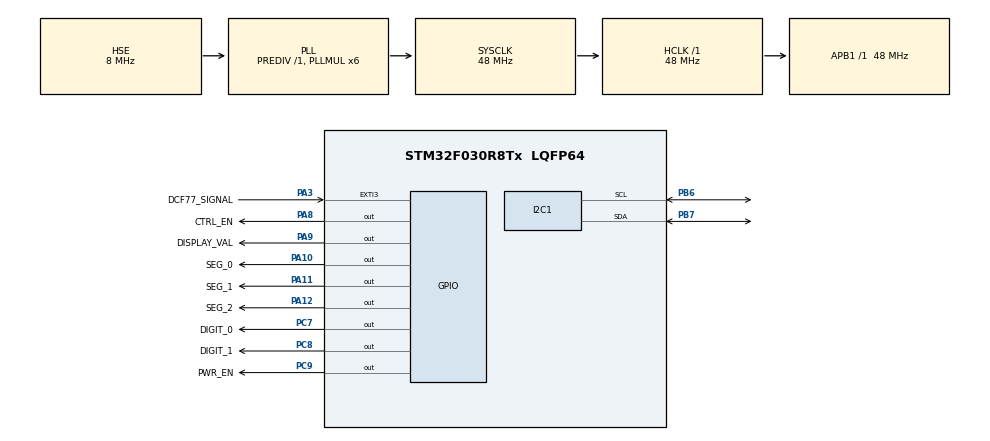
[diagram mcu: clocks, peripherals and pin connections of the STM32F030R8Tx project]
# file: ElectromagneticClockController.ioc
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Mcu.Family=STM32F0
Mcu.Name=STM32F030R8Tx
Mcu.Package=LQFP64
NVIC.EXTI2_3_IRQn=true\:0\:0\:false\:false\:true\:true\:true
NVIC.RTC_IRQn=true\:0\:0\:false\:false\:true\:true\:true
PA10.GPIO_Label=SEG_0
PA10.GPIO_PuPd=GPIO_NOPULL
PA10.Signal=GPIO_Output
PA11.GPIO_Label=SEG_1
PA11.GPIO_PuPd=GPIO_NOPULL
PA11.Signal=GPIO_Output
PA12.GPIO_Label=SEG_2
PA12.GPIO_PuPd=GPIO_NOPULL
PA12.Signal=GPIO_Output
PA13.Mode=Serial_Wire
PA13.Signal=SYS_SWDIO
PA14.Mode=Serial_Wire
PA14.Signal=SYS_SWCLK
PA3.GPIO_Label=DCF77_SIGNAL
PA3.GPIO_ModeDefaultEXTI=GPIO_MODE_IT_RISING_FALLING
PA3.GPIO_PuPd=GPIO_PULLDOWN
PA3.Signal=GPXTI3
PA8.GPIO_Label=CTRL_EN
PA8.GPIO_PuPd=GPIO_NOPULL
PA8.Signal=GPIO_Output
PA9.GPIO_Label=DISPLAY_VAL
PA9.GPIO_PuPd=GPIO_NOPULL
PA9.Signal=GPIO_Output
PB6.Mode=I2C
PB6.Signal=I2C1_SCL
PB7.Mode=I2C
PB7.Signal=I2C1_SDA
PC14-OSC32_IN.Mode=LSE-External-Oscillator
PC14-OSC32_IN.Signal=RCC_OSC32_IN
PC15-OSC32_OUT.Mode=LSE-External-Oscillator
PC15-OSC32_OUT.Signal=RCC_OSC32_OUT
PC7.GPIO_Label=DIGIT_0
PC7.GPIO_PuPd=GPIO_NOPULL
PC7.Signal=GPIO_Output
PC8.GPIO_Label=DIGIT_1
PC8.GPIO_PuPd=GPIO_NOPULL
PC8.Signal=GPIO_Output
PC9.GPIO_Label=PWR_EN
PC9.GPIO_ModeDefaultOutputPP=GPIO_MODE_OUTPUT_PP
PC9.GPIO_PuPd=GPIO_NOPULL
PC9.PinState=GPIO_PIN_RESET
PC9.Signal=GPIO_Output
PF0-OSC_IN.Mode=HSE-External-Oscillator
PF0-OSC_IN.Signal=RCC_OSC_IN
PF1-OSC_OUT.Mode=HSE-External-Oscillator
PF1-OSC_OUT.Signal=RCC_OSC_OUT
ProjectManager.HeapSize=0x200
ProjectManager.StackSize=0x400
ProjectManager.TargetToolchain=STM32CubeIDE
RCC.AHBFreq_Value=48000000
RCC.APB1Freq_Value=48000000
RCC.APB1TimFreq_Value=48000000
RCC.HCLKFreq_Value=48000000
RCC.PLLMUL=RCC_PLL_MUL6
RCC.PLLSourceVirtual=RCC_PLLSOURCE_HSE
RCC.RTCClockSelection=RCC_RTCCLKSOURCE_LSE
RCC.SYSCLKFreq_VALUE=48000000
RCC.SYSCLKSource=RCC_SYSCLKSOURCE_PLLCLK
RTC.Alarm-Alarm\ A=RTC_ALARM_A
RTC.Hours=12
RTC.Minutes=34
VP_RTC_VS_RTC_Activate.Mode=RTC_Enabled
VP_RTC_VS_RTC_Alarm_A_Intern.Mode=Alarm A
VP_RTC_VS_RTC_Calendar.Mode=RTC_Calendar
board=custom

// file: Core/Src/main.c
/* USER CODE BEGIN Header */
/**
  ******************************************************************************
  * @file           : main.c
  * @brief          : Main program body
  ******************************************************************************
  * @attention
  *
  * <h2><center>&copy; Copyright (c) 2020 STMicroelectronics.
  * All rights reserved.</center></h2>
  *
  * This software component is licensed by ST under BSD 3-Clause license,
  * the "License"; You may not use this file except in compliance with the
  * License. You may obtain a copy of the License at:
  *                        opensource.org/licenses/BSD-3-Clause
  *
  ******************************************************************************
  */
/* USER CODE END Header */
#include "main.h"

/* USER CODE BEGIN Includes */
#include "essdisplay.h"
#include "dcf77.h"
#include "rtc.h"

/* USER CODE END Includes */

I2C_HandleTypeDef hi2c1;

RTC_HandleTypeDef hrtc;

void SystemClock_Config(void);
static void MX_GPIO_Init(void);
static void MX_I2C1_Init(void);
static void MX_RTC_Init(void);
/* USER CODE BEGIN PFP */
void Display_Init(void);
/* USER CODE END PFP */

int main(void)
{

  /* MCU Configuration--------------------------------------------------------*/

  /* Reset of all peripherals, Initializes the Flash interface and the Systick. */
  HAL_Init();

  /* Configure the system clock */
  SystemClock_Config();

  /* Initialize all configured peripherals */
  MX_GPIO_Init();
  MX_I2C1_Init();
  MX_RTC_Init();
  /* USER CODE BEGIN 2 */
  ESSDisplay_init();
  RTC_init(&hrtc);
  /* USER CODE END 2 */

  /* Infinite loop */
  while (1)
  {

    /* USER CODE BEGIN 3 */
	  RTC_checkTimeReceived();
	  HAL_Delay(50);
  }
  /* USER CODE END 3 */
}

void SystemClock_Config(void)
{
  RCC_OscInitTypeDef RCC_OscInitStruct = {0};
  RCC_ClkInitTypeDef RCC_ClkInitStruct = {0};
  RCC_PeriphCLKInitTypeDef PeriphClkInit = {0};

  /** Configure LSE Drive Capability
  */
  HAL_PWR_EnableBkUpAccess();
  __HAL_RCC_LSEDRIVE_CONFIG(RCC_LSEDRIVE_HIGH);
  /** Initializes the RCC Oscillators according to the specified parameters
  * in the RCC_OscInitTypeDef structure.
  */
  RCC_OscInitStruct.OscillatorType = RCC_OSCILLATORTYPE_HSI|RCC_OSCILLATORTYPE_HSE
                              |RCC_OSCILLATORTYPE_LSE;
  RCC_OscInitStruct.HSEState = RCC_HSE_ON;
  RCC_OscInitStruct.LSEState = RCC_LSE_ON;
  RCC_OscInitStruct.HSIState = RCC_HSI_ON;
  RCC_OscInitStruct.HSICalibrationValue = RCC_HSICALIBRATION_DEFAULT;
  RCC_OscInitStruct.PLL.PLLState = RCC_PLL_ON;
  RCC_OscInitStruct.PLL.PLLSource = RCC_PLLSOURCE_HSE;
  RCC_OscInitStruct.PLL.PLLMUL = RCC_PLL_MUL6;
  RCC_OscInitStruct.PLL.PREDIV = RCC_PREDIV_DIV1;
  if (HAL_RCC_OscConfig(&RCC_OscInitStruct) != HAL_OK)
  {
    Error_Handler();
  }
  /** Initializes the CPU, AHB and APB buses clocks
  */
  RCC_ClkInitStruct.ClockType = RCC_CLOCKTYPE_HCLK|RCC_CLOCKTYPE_SYSCLK
                              |RCC_CLOCKTYPE_PCLK1;
  RCC_ClkInitStruct.SYSCLKSource = RCC_SYSCLKSOURCE_PLLCLK;
  RCC_ClkInitStruct.AHBCLKDivider = RCC_SYSCLK_DIV1;
  RCC_ClkInitStruct.APB1CLKDivider = RCC_HCLK_DIV1;

  if (HAL_RCC_ClockConfig(&RCC_ClkInitStruct, FLASH_LATENCY_1) != HAL_OK)
  {
    Error_Handler();
  }
  PeriphClkInit.PeriphClockSelection = RCC_PERIPHCLK_I2C1|RCC_PERIPHCLK_RTC;
  PeriphClkInit.I2c1ClockSelection = RCC_I2C1CLKSOURCE_HSI;
  PeriphClkInit.RTCClockSelection = RCC_RTCCLKSOURCE_LSE;
  if (HAL_RCCEx_PeriphCLKConfig(&PeriphClkInit) != HAL_OK)
  {
    Error_Handler();
  }
}

static void MX_I2C1_Init(void)
{

  hi2c1.Instance = I2C1;
  hi2c1.Init.Timing = 0x2000090E;
  hi2c1.Init.OwnAddress1 = 0;
  hi2c1.Init.AddressingMode = I2C_ADDRESSINGMODE_7BIT;
  hi2c1.Init.DualAddressMode = I2C_DUALADDRESS_DISABLE;
  hi2c1.Init.OwnAddress2 = 0;
  hi2c1.Init.OwnAddress2Masks = I2C_OA2_NOMASK;
  hi2c1.Init.GeneralCallMode = I2C_GENERALCALL_DISABLE;
  hi2c1.Init.NoStretchMode = I2C_NOSTRETCH_DISABLE;
  if (HAL_I2C_Init(&hi2c1) != HAL_OK)
  {
    Error_Handler();
  }
  /** Configure Analogue filter
  */
  if (HAL_I2CEx_ConfigAnalogFilter(&hi2c1, I2C_ANALOGFILTER_ENABLE) != HAL_OK)
  {
    Error_Handler();
  }
  /** Configure Digital filter
  */
  if (HAL_I2CEx_ConfigDigitalFilter(&hi2c1, 0) != HAL_OK)
  {
    Error_Handler();
  }

}

static void MX_RTC_Init(void)
{

  RTC_TimeTypeDef sTime = {0};
  RTC_DateTypeDef sDate = {0};
  RTC_AlarmTypeDef sAlarm = {0};

  /** Initialize RTC Only
  */
  hrtc.Instance = RTC;
  hrtc.Init.HourFormat = RTC_HOURFORMAT_24;
  hrtc.Init.AsynchPrediv = 127;
  hrtc.Init.SynchPrediv = 255;
  hrtc.Init.OutPut = RTC_OUTPUT_DISABLE;
  hrtc.Init.OutPutPolarity = RTC_OUTPUT_POLARITY_HIGH;
  hrtc.Init.OutPutType = RTC_OUTPUT_TYPE_OPENDRAIN;
  if (HAL_RTC_Init(&hrtc) != HAL_OK)
  {
    Error_Handler();
  }

  /** Initialize RTC and set the Time and Date
  */
  sTime.Hours = 0x12;
  sTime.Minutes = 0x34;
  sTime.Seconds = 0x0;
  sTime.DayLightSaving = RTC_DAYLIGHTSAVING_NONE;
  sTime.StoreOperation = RTC_STOREOPERATION_RESET;
  if (HAL_RTC_SetTime(&hrtc, &sTime, RTC_FORMAT_BCD) != HAL_OK)
  {
    Error_Handler();
  }
  sDate.WeekDay = RTC_WEEKDAY_MONDAY;
  sDate.Month = RTC_MONTH_JANUARY;
  sDate.Date = 0x1;
  sDate.Year = 0x0;

  if (HAL_RTC_SetDate(&hrtc, &sDate, RTC_FORMAT_BCD) != HAL_OK)
  {
    Error_Handler();
  }
  /** Enable the Alarm A
  */
  sAlarm.AlarmTime.Hours = 0x0;
  sAlarm.AlarmTime.Minutes = 0x0;
  sAlarm.AlarmTime.Seconds = 0x0;
  sAlarm.AlarmTime.SubSeconds = 0x0;
  sAlarm.AlarmTime.DayLightSaving = RTC_DAYLIGHTSAVING_NONE;
  sAlarm.AlarmTime.StoreOperation = RTC_STOREOPERATION_RESET;
  sAlarm.AlarmMask = RTC_ALARMMASK_NONE;
  sAlarm.AlarmSubSecondMask = RTC_ALARMSUBSECONDMASK_ALL;
  sAlarm.AlarmDateWeekDaySel = RTC_ALARMDATEWEEKDAYSEL_DATE;
  sAlarm.AlarmDateWeekDay = 0x1;
  sAlarm.Alarm = RTC_ALARM_A;
  if (HAL_RTC_SetAlarm_IT(&hrtc, &sAlarm, RTC_FORMAT_BCD) != HAL_OK)
  {
    Error_Handler();
  }

}

static void MX_GPIO_Init(void)
{
  GPIO_InitTypeDef GPIO_InitStruct = {0};

  /* GPIO Ports Clock Enable */
  __HAL_RCC_GPIOC_CLK_ENABLE();
  __HAL_RCC_GPIOF_CLK_ENABLE();
  __HAL_RCC_GPIOA_CLK_ENABLE();
  __HAL_RCC_GPIOB_CLK_ENABLE();

  /*Configure GPIO pin Output Level */
  HAL_GPIO_WritePin(GPIOC, DIGIT_0_Pin|DIGIT_1_Pin|PWR_EN_Pin, GPIO_PIN_RESET);

  /*Configure GPIO pin Output Level */
  HAL_GPIO_WritePin(GPIOA, CTRL_EN_Pin|DISPLAY_VAL_Pin|SEG_0_Pin|SEG_1_Pin
                          |SEG_2_Pin, GPIO_PIN_RESET);

  /*Configure GPIO pin : DCF77_SIGNAL_Pin */
  GPIO_InitStruct.Pin = DCF77_SIGNAL_Pin;
  GPIO_InitStruct.Mode = GPIO_MODE_IT_RISING_FALLING;
  GPIO_InitStruct.Pull = GPIO_PULLDOWN;
  HAL_GPIO_Init(DCF77_SIGNAL_GPIO_Port, &GPIO_InitStruct);

  /*Configure GPIO pins : DIGIT_0_Pin DIGIT_1_Pin PWR_EN_Pin */
  GPIO_InitStruct.Pin = DIGIT_0_Pin|DIGIT_1_Pin|PWR_EN_Pin;
  GPIO_InitStruct.Mode = GPIO_MODE_OUTPUT_PP;
  GPIO_InitStruct.Pull = GPIO_NOPULL;
  GPIO_InitStruct.Speed = GPIO_SPEED_FREQ_LOW;
  HAL_GPIO_Init(GPIOC, &GPIO_InitStruct);

  /*Configure GPIO pins : CTRL_EN_Pin DISPLAY_VAL_Pin SEG_0_Pin SEG_1_Pin
                           SEG_2_Pin */
  GPIO_InitStruct.Pin = CTRL_EN_Pin|DISPLAY_VAL_Pin|SEG_0_Pin|SEG_1_Pin
                          |SEG_2_Pin;
  GPIO_InitStruct.Mode = GPIO_MODE_OUTPUT_PP;
  GPIO_InitStruct.Pull = GPIO_NOPULL;
  GPIO_InitStruct.Speed = GPIO_SPEED_FREQ_LOW;
  HAL_GPIO_Init(GPIOA, &GPIO_InitStruct);

  /* EXTI interrupt init*/
  HAL_NVIC_SetPriority(EXTI2_3_IRQn, 0, 0);
  HAL_NVIC_EnableIRQ(EXTI2_3_IRQn);

}

/* USER CODE BEGIN 4 */

void HAL_RTC_AlarmAEventCallback(RTC_HandleTypeDef *hrtc) {
	RTC_handleAlarmEvent(hrtc);
}

/* USER CODE END 4 */

void Error_Handler(void)
{
}

/************************ (C) COPYRIGHT STMicroelectronics *****END OF FILE****/
